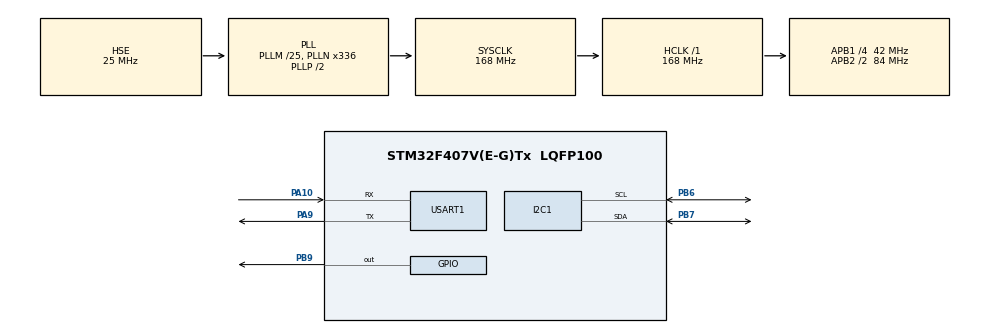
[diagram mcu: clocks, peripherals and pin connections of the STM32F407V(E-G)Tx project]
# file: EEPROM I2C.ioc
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Dma.Request0=USART1_RX
Dma.USART1_RX.0.Direction=DMA_PERIPH_TO_MEMORY
Dma.USART1_RX.0.FIFOMode=DMA_FIFOMODE_DISABLE
Dma.USART1_RX.0.Instance=DMA2_Stream2
Dma.USART1_RX.0.MemDataAlignment=DMA_MDATAALIGN_BYTE
Dma.USART1_RX.0.MemInc=DMA_MINC_ENABLE
Dma.USART1_RX.0.Mode=DMA_CIRCULAR
Dma.USART1_RX.0.PeriphDataAlignment=DMA_PDATAALIGN_BYTE
Dma.USART1_RX.0.PeriphInc=DMA_PINC_DISABLE
Dma.USART1_RX.0.Priority=DMA_PRIORITY_LOW
Mcu.Family=STM32F4
Mcu.Name=STM32F407V(E-G)Tx
Mcu.Package=LQFP100
NVIC.DMA2_Stream2_IRQn=true\:0\:0\:false\:false\:true\:false
NVIC.PriorityGroup=NVIC_PRIORITYGROUP_4
NVIC.USART1_IRQn=true\:0\:0\:false\:false\:true\:true
PA10.Mode=Asynchronous
PA10.Signal=USART1_RX
PA9.Mode=Asynchronous
PA9.Signal=USART1_TX
PB6.Mode=I2C
PB6.Signal=I2C1_SCL
PB7.Mode=I2C
PB7.Signal=I2C1_SDA
PB9.Signal=GPIO_Output
PH0-OSC_IN.Mode=HSE-External-Oscillator
PH0-OSC_IN.Signal=RCC_OSC_IN
PH1-OSC_OUT.Mode=HSE-External-Oscillator
PH1-OSC_OUT.Signal=RCC_OSC_OUT
ProjectManager.HeapSize=0x200
ProjectManager.StackSize=0x400
ProjectManager.TargetToolchain=MDK-ARM V5
RCC.48MHZClocksFreq_Value=84000000
RCC.AHBFreq_Value=168000000
RCC.APB1CLKDivider=RCC_HCLK_DIV4
RCC.APB1Freq_Value=42000000
RCC.APB1TimFreq_Value=84000000
RCC.APB2CLKDivider=RCC_HCLK_DIV2
RCC.APB2Freq_Value=84000000
RCC.APB2TimFreq_Value=168000000
RCC.CortexFreq_Value=168000000
RCC.HCLKFreq_Value=168000000
RCC.HSE_VALUE=25000000
RCC.HSI_VALUE=16000000
RCC.LSE_VALUE=32768
RCC.PLLM=25
RCC.PLLN=336
RCC.PLLSourceVirtual=RCC_PLLSOURCE_HSE
RCC.SYSCLKFreq_VALUE=168000000
RCC.SYSCLKSource=RCC_SYSCLKSOURCE_PLLCLK
RCC.VCOOutputFreq_Value=336000000
USART1.VirtualMode=VM_ASYNC
board=EEPROM I2C

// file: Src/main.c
/**
  ******************************************************************************
  * @file           : main.c
  * @brief          : Main program body
  ******************************************************************************
  ** This notice applies to any and all portions of this file
  * that are not between comment pairs USER CODE BEGIN and
  * USER CODE END. Other portions of this file, whether
  * inserted by the user or by software development tools
  * are owned by their respective copyright owners.
  *
  * COPYRIGHT(c) 2018 STMicroelectronics
  *
  * Redistribution and use in source and binary forms, with or without modification,
  * are permitted provided that the following conditions are met:
  *   1. Redistributions of source code must retain the above copyright notice,
  *      this list of conditions and the following disclaimer.
  *   2. Redistributions in binary form must reproduce the above copyright notice,
  *      this list of conditions and the following disclaimer in the documentation
  *      and/or other materials provided with the distribution.
  *   3. Neither the name of STMicroelectronics nor the names of its contributors
  *      may be used to endorse or promote products derived from this software
  *      without specific prior written permission.
  *
  * THIS SOFTWARE IS PROVIDED BY THE COPYRIGHT HOLDERS AND CONTRIBUTORS "AS IS"
  * AND ANY EXPRESS OR IMPLIED WARRANTIES, INCLUDING, BUT NOT LIMITED TO, THE
  * IMPLIED WARRANTIES OF MERCHANTABILITY AND FITNESS FOR A PARTICULAR PURPOSE ARE
  * DISCLAIMED. IN NO EVENT SHALL THE COPYRIGHT HOLDER OR CONTRIBUTORS BE LIABLE
  * FOR ANY DIRECT, INDIRECT, INCIDENTAL, SPECIAL, EXEMPLARY, OR CONSEQUENTIAL
  * DAMAGES (INCLUDING, BUT NOT LIMITED TO, PROCUREMENT OF SUBSTITUTE GOODS OR
  * SERVICES; LOSS OF USE, DATA, OR PROFITS; OR BUSINESS INTERRUPTION) HOWEVER
  * CAUSED AND ON ANY THEORY OF LIABILITY, WHETHER IN CONTRACT, STRICT LIABILITY,
  * OR TORT (INCLUDING NEGLIGENCE OR OTHERWISE) ARISING IN ANY WAY OUT OF THE USE
  * OF THIS SOFTWARE, EVEN IF ADVISED OF THE POSSIBILITY OF SUCH DAMAGE.
  *
  ******************************************************************************
  */
#include "main.h"
#include "stm32f4xx_hal.h"
#include "stdlib.h"

I2C_HandleTypeDef hi2c1;

UART_HandleTypeDef huart1;
DMA_HandleTypeDef hdma_usart1_rx;

/* USER CODE BEGIN PV */
/* Private variables ---------------------------------------------------------*/
#define EEPROMADDRESS			0xA0
unsigned char dataWrite;
uint8_t dataRead;
unsigned char DataReceived[4];
/* USER CODE END PV */

void SystemClock_Config(void);
static void MX_GPIO_Init(void);
static void MX_DMA_Init(void);
static void MX_I2C1_Init(void);
static void MX_USART1_UART_Init(void);

/* USER CODE BEGIN PFP */
/* Private function prototypes -----------------------------------------------*/

/* USER CODE END PFP */

int main(void)
{

  /* MCU Configuration----------------------------------------------------------*/

  /* Reset of all peripherals, Initializes the Flash interface and the Systick. */
  HAL_Init();

  /* Configure the system clock */
  SystemClock_Config();

  /* Initialize all configured peripherals */
  MX_GPIO_Init();
  MX_DMA_Init();
  MX_I2C1_Init();
  MX_USART1_UART_Init();
  /* USER CODE BEGIN 2 */

	HAL_UART_Receive_DMA(&huart1,DataReceived,sizeof(DataReceived));

/*	while(DataReceived[0]==0){
	HAL_GPIO_TogglePin(GPIOB,GPIO_PIN_9);
	HAL_Delay(100);

	}

	HAL_I2C_Mem_Write(&hi2c1,EEPROMADDRESS,0,0xFF,&DataReceived[0],1,10);
	HAL_Delay(10);
	*/
  HAL_I2C_Mem_Read(&hi2c1,EEPROMADDRESS,0,0xFF,&dataRead,1,1);

  /* USER CODE END 2 */

  /* Infinite loop */
  while (1)
  {

  }

}

void SystemClock_Config(void)
{

  RCC_OscInitTypeDef RCC_OscInitStruct;
  RCC_ClkInitTypeDef RCC_ClkInitStruct;

    /**Configure the main internal regulator output voltage
    */
  __HAL_RCC_PWR_CLK_ENABLE();

  __HAL_PWR_VOLTAGESCALING_CONFIG(PWR_REGULATOR_VOLTAGE_SCALE1);

    /**Initializes the CPU, AHB and APB busses clocks
    */
  RCC_OscInitStruct.OscillatorType = RCC_OSCILLATORTYPE_HSE;
  RCC_OscInitStruct.HSEState = RCC_HSE_ON;
  RCC_OscInitStruct.PLL.PLLState = RCC_PLL_ON;
  RCC_OscInitStruct.PLL.PLLSource = RCC_PLLSOURCE_HSE;
  RCC_OscInitStruct.PLL.PLLM = 25;
  RCC_OscInitStruct.PLL.PLLN = 336;
  RCC_OscInitStruct.PLL.PLLP = RCC_PLLP_DIV2;
  RCC_OscInitStruct.PLL.PLLQ = 4;
  if (HAL_RCC_OscConfig(&RCC_OscInitStruct) != HAL_OK)
  {
    _Error_Handler(__FILE__, __LINE__);
  }

    /**Initializes the CPU, AHB and APB busses clocks
    */
  RCC_ClkInitStruct.ClockType = RCC_CLOCKTYPE_HCLK|RCC_CLOCKTYPE_SYSCLK
                              |RCC_CLOCKTYPE_PCLK1|RCC_CLOCKTYPE_PCLK2;
  RCC_ClkInitStruct.SYSCLKSource = RCC_SYSCLKSOURCE_PLLCLK;
  RCC_ClkInitStruct.AHBCLKDivider = RCC_SYSCLK_DIV1;
  RCC_ClkInitStruct.APB1CLKDivider = RCC_HCLK_DIV4;
  RCC_ClkInitStruct.APB2CLKDivider = RCC_HCLK_DIV2;

  if (HAL_RCC_ClockConfig(&RCC_ClkInitStruct, FLASH_LATENCY_5) != HAL_OK)
  {
    _Error_Handler(__FILE__, __LINE__);
  }

    /**Configure the Systick interrupt time
    */
  HAL_SYSTICK_Config(HAL_RCC_GetHCLKFreq()/1000);

    /**Configure the Systick
    */
  HAL_SYSTICK_CLKSourceConfig(SYSTICK_CLKSOURCE_HCLK);

  /* SysTick_IRQn interrupt configuration */
  HAL_NVIC_SetPriority(SysTick_IRQn, 0, 0);
}

/* I2C1 init function */
static void MX_I2C1_Init(void)
{

  hi2c1.Instance = I2C1;
  hi2c1.Init.ClockSpeed = 100000;
  hi2c1.Init.DutyCycle = I2C_DUTYCYCLE_2;
  hi2c1.Init.OwnAddress1 = 0;
  hi2c1.Init.AddressingMode = I2C_ADDRESSINGMODE_7BIT;
  hi2c1.Init.DualAddressMode = I2C_DUALADDRESS_DISABLE;
  hi2c1.Init.OwnAddress2 = 0;
  hi2c1.Init.GeneralCallMode = I2C_GENERALCALL_DISABLE;
  hi2c1.Init.NoStretchMode = I2C_NOSTRETCH_DISABLE;
  if (HAL_I2C_Init(&hi2c1) != HAL_OK)
  {
    _Error_Handler(__FILE__, __LINE__);
  }

}

/* USART1 init function */
static void MX_USART1_UART_Init(void)
{

  huart1.Instance = USART1;
  huart1.Init.BaudRate = 115200;
  huart1.Init.WordLength = UART_WORDLENGTH_8B;
  huart1.Init.StopBits = UART_STOPBITS_1;
  huart1.Init.Parity = UART_PARITY_NONE;
  huart1.Init.Mode = UART_MODE_TX_RX;
  huart1.Init.HwFlowCtl = UART_HWCONTROL_NONE;
  huart1.Init.OverSampling = UART_OVERSAMPLING_16;
  if (HAL_UART_Init(&huart1) != HAL_OK)
  {
    _Error_Handler(__FILE__, __LINE__);
  }

}

static void MX_DMA_Init(void)
{
  /* DMA controller clock enable */
  __HAL_RCC_DMA2_CLK_ENABLE();

  /* DMA interrupt init */
  /* DMA2_Stream2_IRQn interrupt configuration */
  HAL_NVIC_SetPriority(DMA2_Stream2_IRQn, 0, 0);
  HAL_NVIC_EnableIRQ(DMA2_Stream2_IRQn);

}

/** Configure pins as
        * Analog
        * Input
        * Output
        * EVENT_OUT
        * EXTI
*/
static void MX_GPIO_Init(void)
{

  GPIO_InitTypeDef GPIO_InitStruct;

  /* GPIO Ports Clock Enable */
  __HAL_RCC_GPIOH_CLK_ENABLE();
  __HAL_RCC_GPIOA_CLK_ENABLE();
  __HAL_RCC_GPIOB_CLK_ENABLE();

  /*Configure GPIO pin Output Level */
  HAL_GPIO_WritePin(GPIOB, GPIO_PIN_9, GPIO_PIN_RESET);

  /*Configure GPIO pin : PB9 */
  GPIO_InitStruct.Pin = GPIO_PIN_9;
  GPIO_InitStruct.Mode = GPIO_MODE_OUTPUT_PP;
  GPIO_InitStruct.Pull = GPIO_NOPULL;
  GPIO_InitStruct.Speed = GPIO_SPEED_FREQ_LOW;
  HAL_GPIO_Init(GPIOB, &GPIO_InitStruct);

}

void _Error_Handler(char *file, int line)
{
  while(1)
  {
  }
}

/************************ (C) COPYRIGHT STMicroelectronics *****END OF FILE****/
